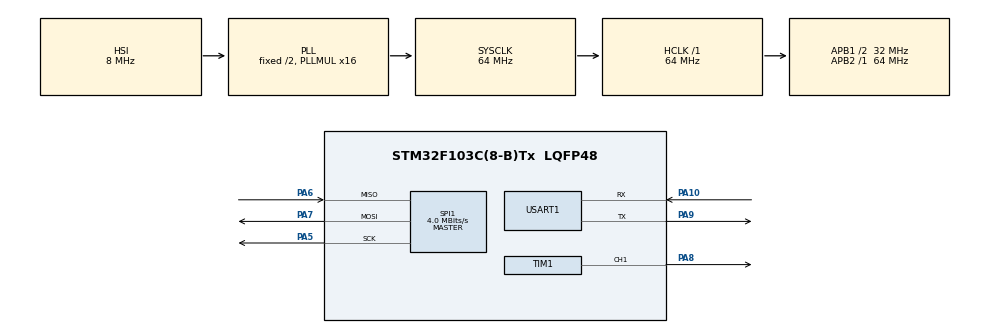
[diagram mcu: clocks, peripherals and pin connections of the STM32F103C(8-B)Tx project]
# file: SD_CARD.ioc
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FATFS._MAX_SS=4096
FATFS._USE_LFN=1
Mcu.Family=STM32F1
Mcu.Name=STM32F103C(8-B)Tx
Mcu.Package=LQFP48
NVIC.PriorityGroup=NVIC_PRIORITYGROUP_4
PA10.Mode=Asynchronous
PA10.Signal=USART1_RX
PA13.Mode=Serial_Wire
PA13.Signal=SYS_JTMS-SWDIO
PA14.Mode=Serial_Wire
PA14.Signal=SYS_JTCK-SWCLK
PA5.Mode=Full_Duplex_Master
PA5.Signal=SPI1_SCK
PA6.Mode=Full_Duplex_Master
PA6.Signal=SPI1_MISO
PA7.Mode=Full_Duplex_Master
PA7.Signal=SPI1_MOSI
PA8.Signal=S_TIM1_CH1
PA9.Mode=Asynchronous
PA9.Signal=USART1_TX
PD0-OSC_IN.Mode=HSE-External-Oscillator
PD0-OSC_IN.Signal=RCC_OSC_IN
PD1-OSC_OUT.Mode=HSE-External-Oscillator
PD1-OSC_OUT.Signal=RCC_OSC_OUT
ProjectManager.HeapSize=0x200
ProjectManager.StackSize=0x400
ProjectManager.TargetToolchain=MDK-ARM V5.32
RCC.AHBFreq_Value=64000000
RCC.APB1CLKDivider=RCC_HCLK_DIV2
RCC.APB1Freq_Value=32000000
RCC.APB1TimFreq_Value=64000000
RCC.APB2Freq_Value=64000000
RCC.APB2TimFreq_Value=64000000
RCC.HCLKFreq_Value=64000000
RCC.PLLMUL=RCC_PLL_MUL16
RCC.SYSCLKFreq_VALUE=64000000
RCC.SYSCLKSource=RCC_SYSCLKSOURCE_PLLCLK
RCC.USBFreq_Value=64000000
SH.S_TIM1_CH1.0=TIM1_CH1,Output Compare1 CH1
SPI1.BaudRatePrescaler=SPI_BAUDRATEPRESCALER_16
SPI1.CalculateBaudRate=4.0 MBits/s
SPI1.Direction=SPI_DIRECTION_2LINES
SPI1.Mode=SPI_MODE_MASTER
SPI1.VirtualType=VM_MASTER
TIM1.Channel-Output\ Compare1\ CH1=TIM_CHANNEL_1
USART1.VirtualMode=VM_ASYNC
VP_FATFS_VS_Generic.Mode=User_defined
VP_TIM1_VS_ClockSourceINT.Mode=Internal
board=custom

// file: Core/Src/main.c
/* USER CODE BEGIN Header */
/**
  ******************************************************************************
  * @file           : main.c
  * @brief          : Main program body
  ******************************************************************************
  * @attention
  *
  * Copyright (c) 2023 STMicroelectronics.
  * All rights reserved.
  *
  * This software is licensed under terms that can be found in the LICENSE file
  * in the root directory of this software component.
  * If no LICENSE file comes with this software, it is provided AS-IS.
  *
  ******************************************************************************
  */
/* USER CODE END Header */
#include "main.h"
#include "fatfs.h"

/* USER CODE BEGIN Includes */
#include "sd.h"
/* USER CODE END Includes */

SPI_HandleTypeDef hspi1;

TIM_HandleTypeDef htim1;

UART_HandleTypeDef huart1;

/* USER CODE BEGIN PV */
FATFS fatfs;
FIL myfile;
FRESULT fresult;
/* USER CODE END PV */

void SystemClock_Config(void);
static void MX_GPIO_Init(void);
static void MX_SPI1_Init(void);
static void MX_USART1_UART_Init(void);
static void MX_TIM1_Init(void);

int main(void)
{

  /* MCU Configuration--------------------------------------------------------*/

  /* Reset of all peripherals, Initializes the Flash interface and the Systick. */
  HAL_Init();

  /* Configure the system clock */
  SystemClock_Config();

  /* Initialize all configured peripherals */
  MX_GPIO_Init();
  MX_SPI1_Init();
  MX_USART1_UART_Init();
  MX_FATFS_Init();
  MX_TIM1_Init();

  /* Infinite loop */
  while (1)
  {

  }
}

void SystemClock_Config(void)
{
  RCC_OscInitTypeDef RCC_OscInitStruct = {0};
  RCC_ClkInitTypeDef RCC_ClkInitStruct = {0};

  /** Initializes the RCC Oscillators according to the specified parameters
  * in the RCC_OscInitTypeDef structure.
  */
  RCC_OscInitStruct.OscillatorType = RCC_OSCILLATORTYPE_HSI;
  RCC_OscInitStruct.HSIState = RCC_HSI_ON;
  RCC_OscInitStruct.HSICalibrationValue = RCC_HSICALIBRATION_DEFAULT;
  RCC_OscInitStruct.PLL.PLLState = RCC_PLL_ON;
  RCC_OscInitStruct.PLL.PLLSource = RCC_PLLSOURCE_HSI_DIV2;
  RCC_OscInitStruct.PLL.PLLMUL = RCC_PLL_MUL16;
  if (HAL_RCC_OscConfig(&RCC_OscInitStruct) != HAL_OK)
  {
    Error_Handler();
  }

  /** Initializes the CPU, AHB and APB buses clocks
  */
  RCC_ClkInitStruct.ClockType = RCC_CLOCKTYPE_HCLK|RCC_CLOCKTYPE_SYSCLK
                              |RCC_CLOCKTYPE_PCLK1|RCC_CLOCKTYPE_PCLK2;
  RCC_ClkInitStruct.SYSCLKSource = RCC_SYSCLKSOURCE_PLLCLK;
  RCC_ClkInitStruct.AHBCLKDivider = RCC_SYSCLK_DIV1;
  RCC_ClkInitStruct.APB1CLKDivider = RCC_HCLK_DIV2;
  RCC_ClkInitStruct.APB2CLKDivider = RCC_HCLK_DIV1;

  if (HAL_RCC_ClockConfig(&RCC_ClkInitStruct, FLASH_LATENCY_2) != HAL_OK)
  {
    Error_Handler();
  }
}

static void MX_SPI1_Init(void)
{

  /* SPI1 parameter configuration*/
  hspi1.Instance = SPI1;
  hspi1.Init.Mode = SPI_MODE_MASTER;
  hspi1.Init.Direction = SPI_DIRECTION_2LINES;
  hspi1.Init.DataSize = SPI_DATASIZE_8BIT;
  hspi1.Init.CLKPolarity = SPI_POLARITY_LOW;
  hspi1.Init.CLKPhase = SPI_PHASE_1EDGE;
  hspi1.Init.NSS = SPI_NSS_SOFT;
  hspi1.Init.BaudRatePrescaler = SPI_BAUDRATEPRESCALER_16;
  hspi1.Init.FirstBit = SPI_FIRSTBIT_MSB;
  hspi1.Init.TIMode = SPI_TIMODE_DISABLE;
  hspi1.Init.CRCCalculation = SPI_CRCCALCULATION_DISABLE;
  hspi1.Init.CRCPolynomial = 10;
  if (HAL_SPI_Init(&hspi1) != HAL_OK)
  {
    Error_Handler();
  }

}

static void MX_TIM1_Init(void)
{

  TIM_ClockConfigTypeDef sClockSourceConfig = {0};
  TIM_MasterConfigTypeDef sMasterConfig = {0};
  TIM_OC_InitTypeDef sConfigOC = {0};
  TIM_BreakDeadTimeConfigTypeDef sBreakDeadTimeConfig = {0};

  htim1.Instance = TIM1;
  htim1.Init.Prescaler = 0;
  htim1.Init.CounterMode = TIM_COUNTERMODE_UP;
  htim1.Init.Period = 65535;
  htim1.Init.ClockDivision = TIM_CLOCKDIVISION_DIV1;
  htim1.Init.RepetitionCounter = 0;
  htim1.Init.AutoReloadPreload = TIM_AUTORELOAD_PRELOAD_DISABLE;
  if (HAL_TIM_Base_Init(&htim1) != HAL_OK)
  {
    Error_Handler();
  }
  sClockSourceConfig.ClockSource = TIM_CLOCKSOURCE_INTERNAL;
  if (HAL_TIM_ConfigClockSource(&htim1, &sClockSourceConfig) != HAL_OK)
  {
    Error_Handler();
  }
  if (HAL_TIM_OC_Init(&htim1) != HAL_OK)
  {
    Error_Handler();
  }
  sMasterConfig.MasterOutputTrigger = TIM_TRGO_RESET;
  sMasterConfig.MasterSlaveMode = TIM_MASTERSLAVEMODE_DISABLE;
  if (HAL_TIMEx_MasterConfigSynchronization(&htim1, &sMasterConfig) != HAL_OK)
  {
    Error_Handler();
  }
  sConfigOC.OCMode = TIM_OCMODE_TIMING;
  sConfigOC.Pulse = 0;
  sConfigOC.OCPolarity = TIM_OCPOLARITY_HIGH;
  sConfigOC.OCNPolarity = TIM_OCNPOLARITY_HIGH;
  sConfigOC.OCFastMode = TIM_OCFAST_DISABLE;
  sConfigOC.OCIdleState = TIM_OCIDLESTATE_RESET;
  sConfigOC.OCNIdleState = TIM_OCNIDLESTATE_RESET;
  if (HAL_TIM_OC_ConfigChannel(&htim1, &sConfigOC, TIM_CHANNEL_1) != HAL_OK)
  {
    Error_Handler();
  }
  sBreakDeadTimeConfig.OffStateRunMode = TIM_OSSR_DISABLE;
  sBreakDeadTimeConfig.OffStateIDLEMode = TIM_OSSI_DISABLE;
  sBreakDeadTimeConfig.LockLevel = TIM_LOCKLEVEL_OFF;
  sBreakDeadTimeConfig.DeadTime = 0;
  sBreakDeadTimeConfig.BreakState = TIM_BREAK_DISABLE;
  sBreakDeadTimeConfig.BreakPolarity = TIM_BREAKPOLARITY_HIGH;
  sBreakDeadTimeConfig.AutomaticOutput = TIM_AUTOMATICOUTPUT_DISABLE;
  if (HAL_TIMEx_ConfigBreakDeadTime(&htim1, &sBreakDeadTimeConfig) != HAL_OK)
  {
    Error_Handler();
  }
  HAL_TIM_MspPostInit(&htim1);

}

static void MX_USART1_UART_Init(void)
{

  huart1.Instance = USART1;
  huart1.Init.BaudRate = 115200;
  huart1.Init.WordLength = UART_WORDLENGTH_8B;
  huart1.Init.StopBits = UART_STOPBITS_1;
  huart1.Init.Parity = UART_PARITY_NONE;
  huart1.Init.Mode = UART_MODE_TX_RX;
  huart1.Init.HwFlowCtl = UART_HWCONTROL_NONE;
  huart1.Init.OverSampling = UART_OVERSAMPLING_16;
  if (HAL_UART_Init(&huart1) != HAL_OK)
  {
    Error_Handler();
  }

}

static void MX_GPIO_Init(void)
{

  /* GPIO Ports Clock Enable */
  __HAL_RCC_GPIOD_CLK_ENABLE();
  __HAL_RCC_GPIOA_CLK_ENABLE();

}

void Error_Handler(void)
{
  __disable_irq();
  while (1)
  {
  }
}
